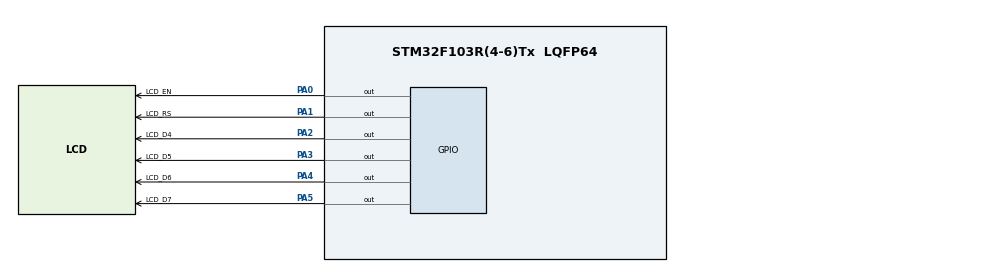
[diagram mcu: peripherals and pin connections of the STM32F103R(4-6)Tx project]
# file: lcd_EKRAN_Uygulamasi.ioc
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Mcu.Family=STM32F1
Mcu.Name=STM32F103R(4-6)Tx
Mcu.Package=LQFP64
NVIC.PriorityGroup=NVIC_PRIORITYGROUP_4
PA0-WKUP.GPIO_Label=LCD_EN
PA0-WKUP.GPIO_Speed=GPIO_SPEED_FREQ_MEDIUM
PA0-WKUP.Signal=GPIO_Output
PA1.GPIO_Label=LCD_RS
PA1.GPIO_Speed=GPIO_SPEED_FREQ_MEDIUM
PA1.Signal=GPIO_Output
PA2.GPIO_Label=LCD_D4
PA2.GPIO_Speed=GPIO_SPEED_FREQ_MEDIUM
PA2.Signal=GPIO_Output
PA3.GPIO_Label=LCD_D5
PA3.GPIO_Speed=GPIO_SPEED_FREQ_MEDIUM
PA3.Signal=GPIO_Output
PA4.GPIO_Label=LCD_D6
PA4.GPIO_Speed=GPIO_SPEED_FREQ_MEDIUM
PA4.Signal=GPIO_Output
PA5.GPIO_Label=LCD_D7
PA5.GPIO_Speed=GPIO_SPEED_FREQ_MEDIUM
PA5.Signal=GPIO_Output
ProjectManager.HeapSize=0x200
ProjectManager.StackSize=0x400
ProjectManager.TargetToolchain=STM32CubeIDE
RCC.APB1Freq_Value=8000000
RCC.APB2Freq_Value=8000000
board=custom

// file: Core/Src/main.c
/* USER CODE BEGIN Header */
/**
  ******************************************************************************
  * @file           : main.c
  * @brief          : Main program body
  ******************************************************************************
  * @attention
  *
  * Copyright (c) 2023 STMicroelectronics.
  * All rights reserved.
  *
  * This software is licensed under terms that can be found in the LICENSE file
  * in the root directory of this software component.
  * If no LICENSE file comes with this software, it is provided AS-IS.
  *
  ******************************************************************************
  */
/* USER CODE END Header */
#include "main.h"

/* USER CODE BEGIN Includes */
#include "lcd.h"

/* USER CODE END Includes */

void SystemClock_Config(void);
static void MX_GPIO_Init(void);

int main(void)
{

  /* MCU Configuration--------------------------------------------------------*/

  /* Reset of all peripherals, Initializes the Flash interface and the Systick. */
  HAL_Init();

  /* Configure the system clock */
  SystemClock_Config();

  /* Initialize all configured peripherals */
  MX_GPIO_Init();
  /* USER CODE BEGIN 2 */
  lcd_init(_LCD_4BIT, _LCD_FONT_5x8, _LCD_2LINE);
  lcd_print(1,1,"kutluay ulutas");
  lcd_print(2,1,"ceng4");
  /* USER CODE END 2 */

  /* Infinite loop */
  while (1)
  {

    /* USER CODE BEGIN 3 */
	 lcd_clear();
	 for(int i=1;i<3;i++){
		 for(int j=1;j<17;j++){
			 lcd_print(i,j,"kuti");
			 HAL_Delay(500);
			 lcd_clear();
		 }
	 }

  }
  /* USER CODE END 3 */
}

void SystemClock_Config(void)
{
  RCC_OscInitTypeDef RCC_OscInitStruct = {0};
  RCC_ClkInitTypeDef RCC_ClkInitStruct = {0};

  /** Initializes the RCC Oscillators according to the specified parameters
  * in the RCC_OscInitTypeDef structure.
  */
  RCC_OscInitStruct.OscillatorType = RCC_OSCILLATORTYPE_HSI;
  RCC_OscInitStruct.HSIState = RCC_HSI_ON;
  RCC_OscInitStruct.HSICalibrationValue = RCC_HSICALIBRATION_DEFAULT;
  RCC_OscInitStruct.PLL.PLLState = RCC_PLL_NONE;
  if (HAL_RCC_OscConfig(&RCC_OscInitStruct) != HAL_OK)
  {
    Error_Handler();
  }

  /** Initializes the CPU, AHB and APB buses clocks
  */
  RCC_ClkInitStruct.ClockType = RCC_CLOCKTYPE_HCLK|RCC_CLOCKTYPE_SYSCLK
                              |RCC_CLOCKTYPE_PCLK1|RCC_CLOCKTYPE_PCLK2;
  RCC_ClkInitStruct.SYSCLKSource = RCC_SYSCLKSOURCE_HSI;
  RCC_ClkInitStruct.AHBCLKDivider = RCC_SYSCLK_DIV1;
  RCC_ClkInitStruct.APB1CLKDivider = RCC_HCLK_DIV1;
  RCC_ClkInitStruct.APB2CLKDivider = RCC_HCLK_DIV1;

  if (HAL_RCC_ClockConfig(&RCC_ClkInitStruct, FLASH_LATENCY_0) != HAL_OK)
  {
    Error_Handler();
  }
}

static void MX_GPIO_Init(void)
{
  GPIO_InitTypeDef GPIO_InitStruct = {0};

  /* GPIO Ports Clock Enable */
  __HAL_RCC_GPIOA_CLK_ENABLE();

  /*Configure GPIO pin Output Level */
  HAL_GPIO_WritePin(GPIOA, LCD_EN_Pin|LCD_RS_Pin|LCD_D4_Pin|LCD_D5_Pin
                          |LCD_D6_Pin|LCD_D7_Pin, GPIO_PIN_RESET);

  /*Configure GPIO pins : LCD_EN_Pin LCD_RS_Pin LCD_D4_Pin LCD_D5_Pin
                           LCD_D6_Pin LCD_D7_Pin */
  GPIO_InitStruct.Pin = LCD_EN_Pin|LCD_RS_Pin|LCD_D4_Pin|LCD_D5_Pin
                          |LCD_D6_Pin|LCD_D7_Pin;
  GPIO_InitStruct.Mode = GPIO_MODE_OUTPUT_PP;
  GPIO_InitStruct.Pull = GPIO_NOPULL;
  GPIO_InitStruct.Speed = GPIO_SPEED_FREQ_MEDIUM;
  HAL_GPIO_Init(GPIOA, &GPIO_InitStruct);

}

void Error_Handler(void)
{
  __disable_irq();
  while (1)
  {
  }
}
